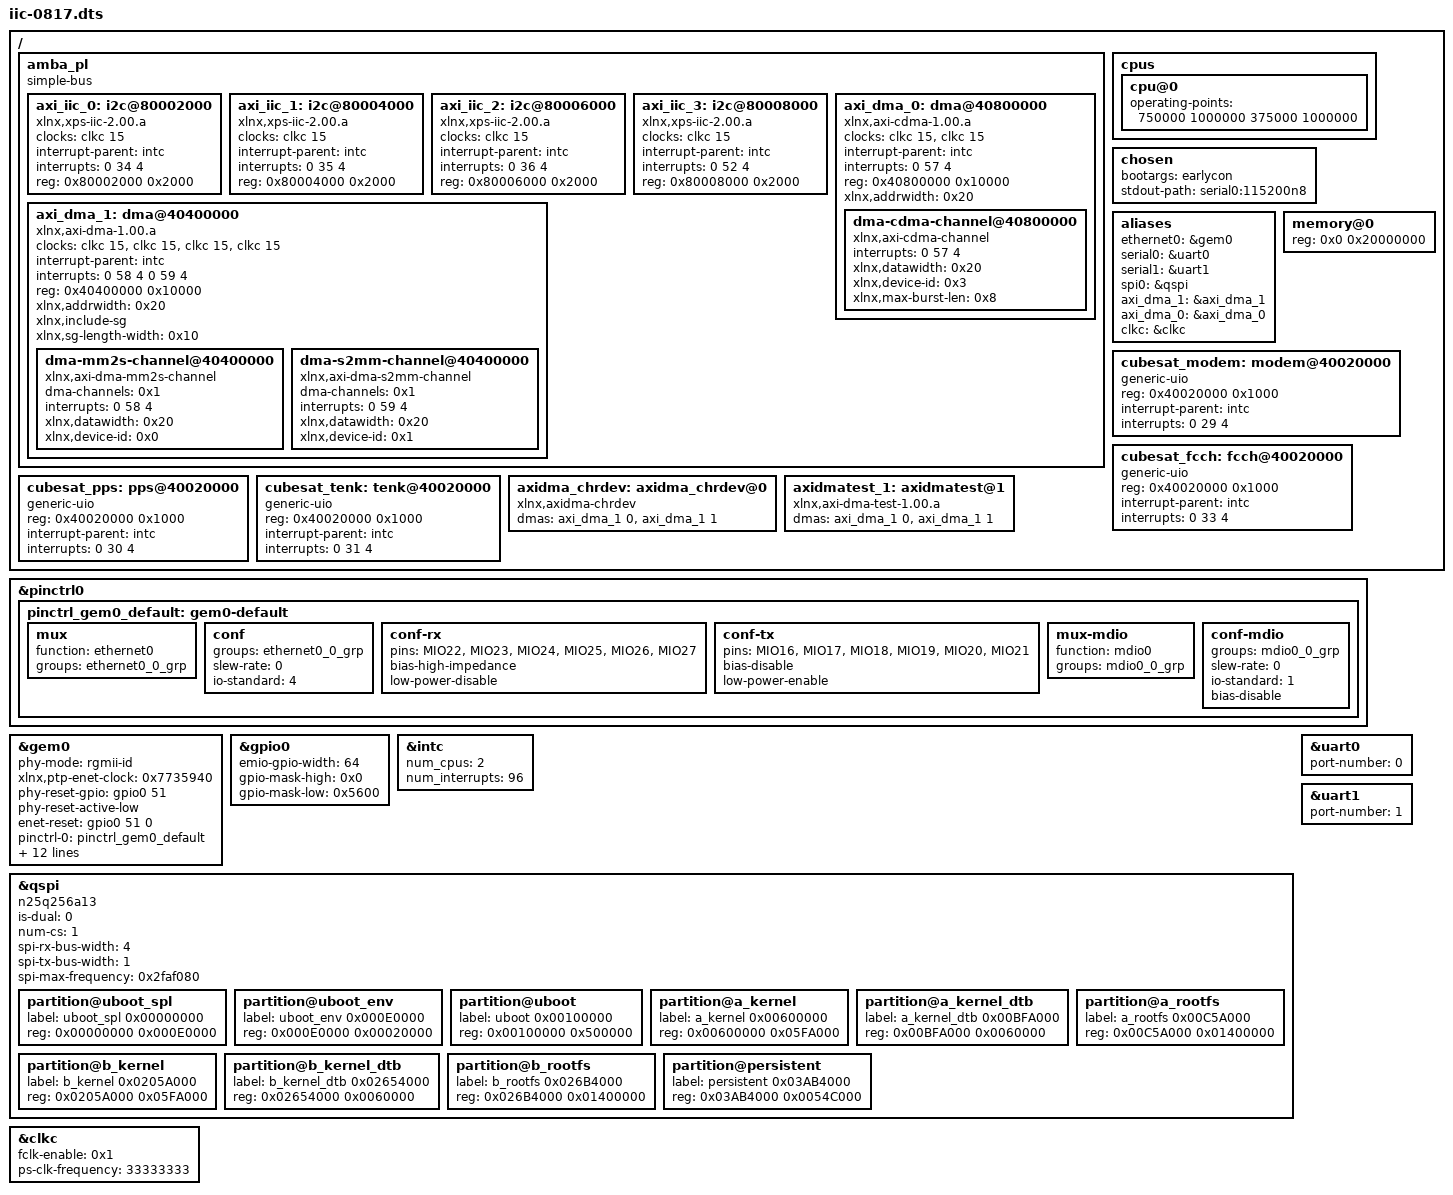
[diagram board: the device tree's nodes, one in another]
/*
 * CAUTION: This file is automatically generated by Xilinx.
 * Version: HSI 2017.4
 * Today is: Tue Jul 24 16:42:53 2018
 */


/dts-v1/;
/include/ "zynq-7000.dtsi"
/ {
	amba_pl: amba_pl {
		#address-cells = <1>;
		#size-cells = <1>;
		compatible = "simple-bus";
		ranges ;

		axi_iic_0: i2c@80002000 {
			#address-cells = <1>;
			#size-cells = <0>;
			clock-names = "ref_clk";
			clocks = <&clkc 15>;
			compatible = "xlnx,xps-iic-2.00.a";
			interrupt-parent = <&intc>;
			interrupts = <0 34 4>;
			reg = <0x80002000 0x2000>;
		};
		axi_iic_1: i2c@80004000 {
			#address-cells = <1>;
			#size-cells = <0>;
			clock-names = "ref_clk";
			clocks = <&clkc 15>;
			compatible = "xlnx,xps-iic-2.00.a";
			interrupt-parent = <&intc>;
			interrupts = <0 35 4>;
			reg = <0x80004000 0x2000>;
		};
		axi_iic_2: i2c@80006000 {
			#address-cells = <1>;
			#size-cells = <0>;
			clock-names = "ref_clk";
			clocks = <&clkc 15>;
			compatible = "xlnx,xps-iic-2.00.a";
			interrupt-parent = <&intc>;
			interrupts = <0 36 4>;
			reg = <0x80006000 0x2000>;
		};
		axi_iic_3: i2c@80008000 {
			#address-cells = <1>;
			#size-cells = <0>;
			clock-names = "ref_clk";
			clocks = <&clkc 15>;
			compatible = "xlnx,xps-iic-2.00.a";
			interrupt-parent = <&intc>;
			interrupts = <0 52 4>;
			reg = <0x80008000 0x2000>;
		};


		axi_dma_0: dma@40800000 {
			#dma-cells = <1>;
			clock-names = "s_axi_lite_aclk", "m_axi_aclk";
                        /*  added clocks */ 
                        clocks = <&clkc 15>, <&clkc 15>;
			compatible = "xlnx,axi-cdma-1.00.a";
			interrupt-names = "cdma_introut";
			interrupt-parent = <&intc>;
			interrupts = <0 57 4>;
			reg = <0x40800000 0x10000>;
			xlnx,addrwidth = <0x20>;
			/* orig: dma-channel@40800000 { */ 
			dma-cdma-channel@40800000 {
				compatible = "xlnx,axi-cdma-channel";
				interrupts = <0 57 4>;
				xlnx,datawidth = <0x20>;
                                /* change device-id to 0x3 */ 
				xlnx,device-id = <0x3>;
				xlnx,max-burst-len = <0x8>;
			};
		};
 		/* orig: ps_bd_ps_bd_i_ps_eth_dma_0: dma@40400000 { */
 		axi_dma_1: dma@40400000 {
			#dma-cells = <1>;
			clock-names = "s_axi_lite_aclk", "m_axi_sg_aclk", "m_axi_mm2s_aclk", "m_axi_s2mm_aclk";
                        /* added clocks */
                        clocks = <&clkc 15>, <&clkc 15>, <&clkc 15>, <&clkc 15>;
			compatible = "xlnx,axi-dma-1.00.a";
			interrupt-names = "mm2s_introut", "s2mm_introut";
			interrupt-parent = <&intc>;
			interrupts = <0 58 4 0 59 4>;
			reg = <0x40400000 0x10000>;
			xlnx,addrwidth = <0x20>;
			xlnx,include-sg ;
			xlnx,sg-length-width = <0x10>;
			/* orig: dma-channel@40400000 { */
			dma-mm2s-channel@40400000 {
				compatible = "xlnx,axi-dma-mm2s-channel";
				dma-channels = <0x1>;
				interrupts = <0 58 4>;
				xlnx,datawidth = <0x20>;
				xlnx,device-id = <0x0>;
			};
			/* orig: dma-channel@40400030 { */
			dma-s2mm-channel@40400000 {
				compatible = "xlnx,axi-dma-s2mm-channel";
				dma-channels = <0x1>;
				interrupts = <0 59 4>;
				xlnx,datawidth = <0x20>;
                                /* change device-id to 0x1 from 0x0 */
				xlnx,device-id = <0x1>;
			};
		};
	};
};
/ {
	cpus {
		cpu@0 {
			operating-points = <750000 1000000 375000 1000000>;
		};
	};
};
&pinctrl0 {
	pinctrl_gem0_default: gem0-default {
 		mux {
 			function = "ethernet0";
 			groups = "ethernet0_0_grp";
 		};
 
		conf {
 		groups = "ethernet0_0_grp";
 			slew-rate = <0>;
 			io-standard = <4>;
 		};
 
 		conf-rx {
 			pins = "MIO22", "MIO23", "MIO24", "MIO25", "MIO26", "MIO27";
 			bias-high-impedance;
			low-power-disable;
 		};
 
 		conf-tx {
 			pins = "MIO16", "MIO17", "MIO18", "MIO19", "MIO20", "MIO21";
 			bias-disable;
 			low-power-enable;
 		};
 
 		mux-mdio {
 			function = "mdio0";
 			groups = "mdio0_0_grp";
 		};
 
 		conf-mdio {
 			groups = "mdio0_0_grp";
 			slew-rate = <0>;
 			io-standard = <1>;
 			bias-disable;
 		};
 	};
};
 
&gem0 {
	phy-mode = "rgmii-id";
	status = "okay";
	xlnx,ptp-enet-clock = <0x7735940>;
        phy-reset-gpio = <&gpio0 51 0>;
        phy-reset-active-low;
        enet-reset = <&gpio0 51 0>;
        pinctrl-names = "default";
        pinctrl-0 = <&pinctrl_gem0_default>;
 
 	txc-skew-ps  = <900>; /*    0 ps was -540 ps */
 	rxc-skew-ps  = <900>; /*    0 ps */
 
 	txen-skew-ps = <420>; /*    0 ps */
 	rxdv-skew-ps = <420>; /*    0 ps */
 
 	txd0-skew-ps = <420>; /*    0 ps */
 	txd1-skew-ps = <420>; /*    0 ps */
 	txd2-skew-ps = <420>; /*    0 ps */
 	txd3-skew-ps = <420>; /*    0 ps */
 
 	rxd0-skew-ps = <420>; /*    0 ps */
 	rxd1-skew-ps = <420>; /*    0 ps */
 	rxd2-skew-ps = <420>; /*    0 ps */
 	rxd3-skew-ps = <420>; /*    0 ps */
/*
        phy-handle = <&phy0>;
 
        phy0: phy@7 {
             reg = <7>;
             compatible = "micrel,ksz9031";
             device_type = "ethernet-phy";
        };
*/
};
&gpio0 {
	emio-gpio-width = <64>;
	gpio-mask-high = <0x0>;
	gpio-mask-low = <0x5600>;
};
&intc {
	num_cpus = <2>;
	num_interrupts = <96>;
};
&qspi {
        compatible = "n25q256a13", "jedec,spi-nor";
	is-dual = <0>;
	num-cs = <1>;
	spi-rx-bus-width = <4>;
	spi-tx-bus-width = <1>;
	status = "okay";
        spi-max-frequency = <0x2faf080>;
        #address-cells = <0x1>;
        #size-cells = <0x1>;
        /****
         * partitions lifted from OPAT device tree
         ****/
	partition@uboot_spl {
		label = "uboot_spl      0x00000000";
		reg = <0x00000000 0x000E0000>;
	};
	partition@uboot_env {
		label = "uboot_env      0x000E0000";
		reg = <0x000E0000 0x00020000>;
	};
	partition@uboot {
		label = "uboot          0x00100000";
		reg = <0x00100000 0x500000>;
	};
	partition@a_kernel {
		label = "a_kernel       0x00600000";
		reg = <0x00600000 0x05FA000>;
	};
	partition@a_kernel_dtb {
		label = "a_kernel_dtb   0x00BFA000";
		reg = <0x00BFA000 0x0060000>;
	};
	partition@a_rootfs {
		label = "a_rootfs       0x00C5A000";
		reg = <0x00C5A000 0x01400000>;
	};
	partition@b_kernel {
		label = "b_kernel       0x0205A000";
		reg = <0x0205A000     0x05FA000>;
	};
	partition@b_kernel_dtb {
		label = "b_kernel_dtb   0x02654000";
			reg = <0x02654000 0x0060000>;
	};
	partition@b_rootfs {
		label = "b_rootfs       0x026B4000";
		reg = <0x026B4000 0x01400000>;
	};
	partition@persistent {
		label = "persistent     0x03AB4000";
		reg = <0x03AB4000 0x0054C000>;
	};
};

/*
&spi0 {
	is-decoded-cs = <0>;
	num-cs = <3>;
	status = "okay";
};
&spi1 {
	is-decoded-cs = <0>;
	num-cs = <3>;
	status = "okay";
};
*/
&uart0 {
	device_type = "serial";
	port-number = <0>;
	status = "okay";
};
&uart1 {
	device_type = "serial";
	port-number = <1>;
	status = "okay";
};
&clkc {
        fclk-enable = <0x1>;
	ps-clk-frequency = <33333333>;
};
/ {
	chosen {
		bootargs = "earlycon";
		stdout-path = "serial0:115200n8";
	};
	aliases {
		ethernet0 = &gem0;
		serial0 = &uart0;
		serial1 = &uart1;
		spi0 = &qspi;
/*
		spi1 = &spi0;
		spi2 = &spi1;
*/
                axi_dma_1 = &axi_dma_1;
                axi_dma_0 = &axi_dma_0;
                clkc = &clkc;
	};
	memory@0 {
                /* u-boot,dm-pre-reloc; */
		device_type = "memory";
		reg = <0x0 0x20000000>;
	};

        /*** /dev/uio0 ***/
        cubesat_modem: modem@40020000 {
                compatible = "generic-uio","uio";
                reg = < 0x40020000 0x1000 >;
                interrupt-parent = <&intc>;
                interrupts = < 0 29 4 >;
        };

        /*** /dev/uio1 ***/
        cubesat_fcch: fcch@40020000 {
                compatible = "generic-uio","uio";
                reg = < 0x40020000 0x1000 >;
                interrupt-parent = <&intc>;
                interrupts = < 0 33 4 >;
        };

        /*** /dev/uio2 ***/
        cubesat_pps: pps@40020000 {
                compatible = "generic-uio","uio";
                reg = < 0x40020000 0x1000 >;
                interrupt-parent = <&intc>;
                interrupts = < 0 30 4 >;
        };

        /*** /dev/uio3 ***/
        cubesat_tenk: tenk@40020000 {
                compatible = "generic-uio","uio";
                reg = < 0x40020000 0x1000 >;
                interrupt-parent = <&intc>;
                interrupts = < 0 31 4 >;
        };

        axidma_chrdev: axidma_chrdev@0 {
            compatible = "xlnx,axidma-chrdev";
            dmas = <&axi_dma_1 0 &axi_dma_1 1>;
            dma-names = "tx_channel", "rx_channel";
        };

        /* added manually for axidma tester */
        axidmatest_1: axidmatest@1 {
            compatible ="xlnx,axi-dma-test-1.00.a";
            dmas = <&axi_dma_1 0 &axi_dma_1 1>;
            dma-names = "axidma0", "axidma1";
        };
};
